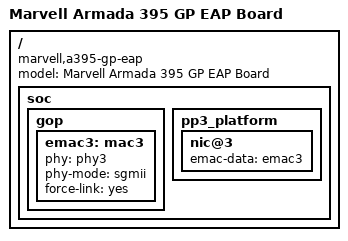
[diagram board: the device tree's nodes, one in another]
/*
 * Device Tree file for Marvell Armada 395 GP EAP board
 * (DB-88F6925-EAP-10G)
 *
 * Copyright (C) 2016 Marvell
 *
 * Grzegorz Jaszczyk <jaz@semihalf.com>
 *
 * This file is dual-licensed: you can use it either under the terms
 * of the GPL or the X11 license, at your option. Note that this dual
 * licensing only applies to this file, and not this project as a
 * whole.
 *
 *  a) This file is licensed under the terms of the GNU General Public
 *     License version 2.  This program is licensed "as is" without
 *     any warranty of any kind, whether express or implied.
 *
 * Or, alternatively,
 *
 *  b) Permission is hereby granted, free of charge, to any person
 *     obtaining a copy of this software and associated documentation
 *     files (the "Software"), to deal in the Software without
 *     restriction, including without limitation the rights to use,
 *     copy, modify, merge, publish, distribute, sublicense, and/or
 *     sell copies of the Software, and to permit persons to whom the
 *     Software is furnished to do so, subject to the following
 *     conditions:
 *
 *     The above copyright notice and this permission notice shall be
 *     included in all copies or substantial portions of the Software.
 *
 *     THE SOFTWARE IS PROVIDED "AS IS", WITHOUT WARRANTY OF ANY KIND,
 *     EXPRESS OR IMPLIED, INCLUDING BUT NOT LIMITED TO THE WARRANTIES
 *     OF MERCHANTABILITY, FITNESS FOR A PARTICULAR PURPOSE AND
 *     NONINFRINGEMENT. IN NO EVENT SHALL THE AUTHORS OR COPYRIGHT
 *     HOLDERS BE LIABLE FOR ANY CLAIM, DAMAGES OR OTHER LIABILITY,
 *     WHETHER IN AN ACTION OF CONTRACT, TORT OR OTHERWISE, ARISING
 *     FROM, OUT OF OR IN CONNECTION WITH THE SOFTWARE OR THE USE OR
 *     OTHER DEALINGS IN THE SOFTWARE.
 */

/dts-v1/;
#include "armada-395-gp.dtsi"

/ {
	model = "Marvell Armada 395 GP EAP Board";
	compatible = "marvell,a395-gp-eap", "marvell,armada395", "marvell,armada380";

	soc {
		gop {
			emac3: mac3 {
				phy = <&phy3>;
				phy-mode = "sgmii";
				force-link = "yes";
			};
		};

		pp3_platform {
			nic@3 {
				status = "okay";
				emac-data = <&emac3>;
			};
		};
	};
};
